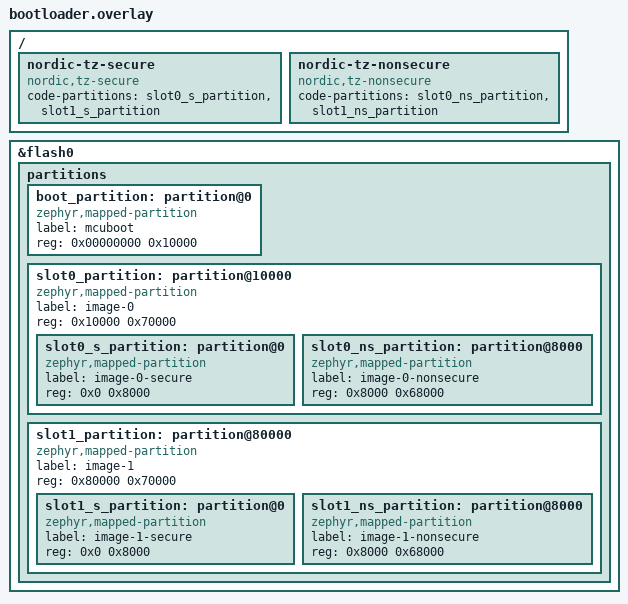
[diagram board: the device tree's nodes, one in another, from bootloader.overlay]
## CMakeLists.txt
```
#
# Copyright (c) 2019 Nordic Semiconductor
#
# SPDX-License-Identifier: LicenseRef-Nordic-5-Clause
#

cmake_minimum_required(VERSION 3.20.0)

find_package(Zephyr REQUIRED HINTS $ENV{ZEPHYR_BASE})
project(lwm2m-carrier)

# Generate hex files from pem files
set(gen_dir ${CMAKE_CURRENT_BINARY_DIR}/certs)
zephyr_include_directories(${gen_dir})
generate_inc_file_for_target(
    app
    certs/DigiCertGlobalRootCA.pem
    ${gen_dir}/DigiCertGlobalRootCA.pem.inc
    )
generate_inc_file_for_target(
    app
    certs/DigiCertGlobalRootG2.pem
    ${gen_dir}/DigiCertGlobalRootG2.pem.inc
    )
generate_inc_file_for_target(
    app
    certs/DSTRootCA-X3.pem
    ${gen_dir}/DSTRootCA-X3.pem.inc
    )

# NORDIC SDK APP START
target_sources(app PRIVATE src/main.c)
target_sources(app PRIVATE src/carrier_certs.c)
# NORDIC SDK APP END
```

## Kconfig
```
#
# Copyright (c) 2022 Nordic Semiconductor ASA
#
# SPDX-License-Identifier: LicenseRef-Nordic-5-Clause
#

menu "Custom PSK"
config CARRIER_APP_PSK
	string "LwM2M Pre-Shared Key (PSK)"
	default ""
	help
	  Hexadecimal PSK used to connect to the LwM2M server.

endmenu

menu "Zephyr Kernel"
source "Kconfig.zephyr"
endmenu
```

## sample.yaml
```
sample:
  name: LwM2M carrier sample
tests:
  sample.cellular.lwm2m_carrier:
    sysbuild: true
    build_only: true
    integration_platforms:
      - nrf9151dk/nrf9151/ns
    platform_allow:
      - nrf9151dk/nrf9151/ns
    tags:
      - ci_build
      - sysbuild
      - ci_samples_cellular
  sample.cellular.lwm2m_carrier.shell:
    sysbuild: true
    build_only: true
    integration_platforms:
      - nrf9151dk/nrf9151/ns
    platform_allow:
      - nrf9151dk/nrf9151/ns
    extra_args: EXTRA_CONF_FILE="overlay-shell.conf"
    tags:
      - ci_build
      - sysbuild
      - ci_samples_cellular
  sample.cellular.lwm2m_carrier.softbank:
    sysbuild: true
    build_only: true
    integration_platforms:
      - nrf9151dk/nrf9151/ns
    platform_allow:
      - nrf9151dk/nrf9151/ns
    extra_args:
      - EXTRA_CONF_FILE="overlay-softbank.conf"
      - SB_EXTRA_CONF_FILE="sysbuild-softbank.conf"
      - EXTRA_DTC_OVERLAY_FILE="bootloader.overlay"
    tags:
      - ci_build
      - sysbuild
      - ci_samples_cellular
  sample.cellular.lwm2m_carrier.lgu:
    sysbuild: true
    build_only: true
    integration_platforms:
      - nrf9151dk/nrf9151/ns
    platform_allow:
      - nrf9151dk/nrf9151/ns
    extra_args:
      - EXTRA_CONF_FILE="overlay-lgu.conf"
      - SB_EXTRA_CONF_FILE="sysbuild-lgu.conf"
      - EXTRA_DTC_OVERLAY_FILE="bootloader.overlay"
    tags:
      - ci_build
      - sysbuild
      - ci_samples_cellular
```

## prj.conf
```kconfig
#
# Copyright (c) 2019 Nordic Semiconductor ASA
#
# SPDX-License-Identifier: LicenseRef-Nordic-5-Clause
#

# TF-M config
CONFIG_TFM_PROFILE_TYPE_MINIMAL=y

CONFIG_LWM2M_CARRIER=y

# LwM2M carrier is only compiled for hard-float
CONFIG_FPU=y
CONFIG_FP_HARDABI=y

# Modem library
CONFIG_NRF_MODEM_LIB=y

# LTE link control
CONFIG_LTE_LINK_CONTROL=y
CONFIG_LTE_LC_PDN_MODULE=y

# SMS library
CONFIG_SMS=y

# Download client for DFU
CONFIG_DOWNLOADER=y
CONFIG_DOWNLOADER_MAX_FILENAME_SIZE=230

# AT Monitor
CONFIG_AT_MONITOR=y
CONFIG_AT_MONITOR_HEAP_SIZE=320

# Credential management
CONFIG_MODEM_KEY_MGMT=y

# Non-volatile Storage
CONFIG_FLASH=y
CONFIG_FLASH_PAGE_LAYOUT=y
CONFIG_NVS=y
CONFIG_MPU_ALLOW_FLASH_WRITE=y

# Heap and stacks
CONFIG_HEAP_MEM_POOL_SIZE=4096
CONFIG_SYSTEM_WORKQUEUE_STACK_SIZE= 1536
CONFIG_MAIN_STACK_SIZE=1536

# General config
CONFIG_NETWORKING=y
CONFIG_NET_NATIVE=n
CONFIG_NET_SOCKETS=y
CONFIG_POSIX_API=y
CONFIG_NET_SOCKETS_OFFLOAD=y

# Allow the non-secure application to request reboot
CONFIG_REBOOT=y

# DFU target library
CONFIG_DFU_TARGET=y

# IPv4 (IPv6 is enabled by default)
CONFIG_NET_IPV4=y
```

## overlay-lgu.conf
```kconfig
#
# Copyright (c) 2024 Nordic Semiconductor
#
# SPDX-License-Identifier: LicenseRef-Nordic-5-Clause
#

# LG U+
CONFIG_LWM2M_CARRIER_LG_UPLUS=y

# Application FOTA
CONFIG_DFU_TARGET_MCUBOOT=y
CONFIG_IMG_MANAGER=y
CONFIG_STREAM_FLASH=y
CONFIG_STREAM_FLASH_ERASE=y
CONFIG_FLASH_MAP=y
```

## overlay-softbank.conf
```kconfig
#
# Copyright (c) 2024 Nordic Semiconductor
#
# SPDX-License-Identifier: LicenseRef-Nordic-5-Clause
#

# SoftBank
CONFIG_LWM2M_CARRIER_SOFTBANK=y
CONFIG_LWM2M_CARRIER_SOFTBANK_DIVIDED_FOTA=y

# Override default PDP context
CONFIG_LTE_LC_PDN_DEFAULTS_OVERRIDE=y
CONFIG_LTE_LC_PDN_DEFAULT_FAM_NONIP=y

# Set NB-IoT system mode
CONFIG_LTE_NETWORK_MODE_NBIOT=y

# Application FOTA
CONFIG_DFU_TARGET_MCUBOOT=y
CONFIG_BOOTLOADER_MCUBOOT=y
CONFIG_IMG_MANAGER=y
CONFIG_STREAM_FLASH=y
CONFIG_STREAM_FLASH_ERASE=y
CONFIG_FLASH_MAP=y
```

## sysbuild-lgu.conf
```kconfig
#
# Copyright (c) 2019 Nordic Semiconductor ASA
#
# SPDX-License-Identifier: LicenseRef-Nordic-5-Clause
#

SB_CONFIG_BOOTLOADER_MCUBOOT=y
```

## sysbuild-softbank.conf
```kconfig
#
# Copyright (c) 2019 Nordic Semiconductor ASA
#
# SPDX-License-Identifier: LicenseRef-Nordic-5-Clause
#

SB_CONFIG_LWM2M_CARRIER_DIVIDED_DFU=y
SB_CONFIG_BOOTLOADER_MCUBOOT=y
```

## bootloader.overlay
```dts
/*
 * Copyright (c) 2026 Nordic Semiconductor ASA
 *
 * SPDX-License-Identifier: LicenseRef-Nordic-5-Clause
 */

/delete-node/ &slot0_partition;

&flash0 {
	/*
	 * Replace single slot0 with boot, slot0 and slot1. (Keep storage_partition the same).
	 *
	 * 0x0000_0000  MCUboot                        ( 65 kB)
	 * 0x0000_c000  Primary area                   (448 kB)
	 *   0x0000_c000  Primary secure image         ( 32 kB)
	 *   0x0001_8000  Primary non-secure image     (416 kB)
	 * 0x0007_5000  Secondary area                 (448 kB)
	 *    0x0007_5000  Secondary secure image      ( 32 kB)
	 *    0x0008_1000  Secondary non-secure image  (416 kB)
	 */
	partitions {
		ranges;
		#address-cells = <1>;
		#size-cells = <1>;

		boot_partition: partition@0 {
			compatible = "zephyr,mapped-partition";
			label = "mcuboot";
			reg = <0x00000000 0x10000>;
		};

		slot0_partition: partition@10000 {
			compatible = "zephyr,mapped-partition";
			label = "image-0";
			reg = <0x10000 0x70000>;
			ranges = <0x0 0x10000 0x70000>;
			#address-cells = <1>;
			#size-cells = <1>;

			slot0_s_partition: partition@0 {
				compatible = "zephyr,mapped-partition";
				label = "image-0-secure";
				reg = <0x0 0x8000>;
			};

			slot0_ns_partition: partition@8000 {
				compatible = "zephyr,mapped-partition";
				label = "image-0-nonsecure";
				reg = <0x8000 0x68000>;
			};
		};

		slot1_partition: partition@80000 {
			compatible = "zephyr,mapped-partition";
			label = "image-1";
			reg = <0x80000 0x70000>;
			ranges = <0x0 0x80000 0x70000>;
			#address-cells = <1>;
			#size-cells = <1>;

			slot1_s_partition: partition@0 {
				compatible = "zephyr,mapped-partition";
				label = "image-1-secure";
				reg = <0x0 0x8000>;
			};

			slot1_ns_partition: partition@8000 {
				compatible = "zephyr,mapped-partition";
				label = "image-1-nonsecure";
				reg = <0x8000 0x68000>;
			};
		};
	};
};

/ {
	/delete-node/ nordic-tz-secure;
	/delete-node/ nordic-tz-nonsecure;

	nordic-tz-secure {
		compatible = "nordic,tz-secure";
		code-partitions = <&slot0_s_partition>,
				  <&slot1_s_partition>;
	};

	nordic-tz-nonsecure {
		compatible = "nordic,tz-nonsecure";
		code-partitions = <&slot0_ns_partition>,
				  <&slot1_ns_partition>;
	};
};
```

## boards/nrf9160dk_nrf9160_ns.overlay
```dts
/*
 * Copyright (c) 2026 Nordic Semiconductor ASA
 *
 * SPDX-License-Identifier: LicenseRef-Nordic-5-Clause
 */

#include <samples/cellular/nrf91_no_bootloader_partitions.dtsi>

/ {
	chosen {
		nordic,lwm2m-carrier-partition = &lwm2m_carrier_partition;
		zephyr,settings-partition = &settings_storage_partition;
	};
};

&storage_partition {
	compatible = "zephyr,mapped-partition";
	label = "storage";
	reg = <0x000f8000 0x8000>;
	ranges = <0x0 0x000f8000 0x8000>;
	#address-cells = <1>;
	#size-cells = <1>;

	lwm2m_carrier_partition: partition@0 {
		compatible = "zephyr,mapped-partition";
		label = "lwm2m-carrier";
		reg = <0x00000000 0x3000>;
	};

	settings_storage_partition: partition@3000 {
		compatible = "zephyr,mapped-partition";
		label = "settings-storage";
		reg = <0x00003000 0x5000>;
	};
};

#include <samples/cellular/nrf91_sram_partitions.dtsi>
```

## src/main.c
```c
/*
 * Copyright (c) 2019 Nordic Semiconductor ASA
 *
 * SPDX-License-Identifier: LicenseRef-Nordic-5-Clause
 */

#include <zephyr/kernel.h>
#include <modem/nrf_modem_lib.h>
#include <modem/lte_lc.h>

#ifdef CONFIG_LWM2M_CARRIER
#include <lwm2m_carrier.h>
#include "carrier_certs.h"

NRF_MODEM_LIB_ON_INIT(main_init_hook, on_modem_lib_init, NULL);

static void lte_event_handler(const struct lte_lc_evt *const evt)
{
	/* This event handler is not in use here. */
	ARG_UNUSED(evt);
}

static void on_modem_lib_init(int ret, void *ctx)
{
	int err;
	static bool m_first_init = true;

	ARG_UNUSED(ctx);

	if (ret != 0) {
		printk("Modem library did not initialize: %d\n", ret);
		return;
	}

	/* Let the application write the credentials first and then bring the link up! */
	if (m_first_init) {
		err = carrier_cert_provision();
		if (err) {
			printk("failed to provision CA certificates\n");
		}

#ifdef LWM2M_CARRIER_SETTINGS
		if (!lwm2m_settings_enable_custom_server_config_get()) {
			err = carrier_psk_provision();
			if (err) {
				printk("failed to provision PSK\n");
			}
		}
#else
		err = carrier_psk_provision();
		if (err) {
			printk("failed to provision PSK\n");
		}
#endif /* LWM2M_CARRIER_SETTINGS */

		lte_lc_register_handler(lte_event_handler);

		m_first_init = false;
	}
}

void print_err(const lwm2m_carrier_event_t *evt)
{
	const lwm2m_carrier_event_error_t *err = evt->data.error;

	static const char *strerr[] = {
		[LWM2M_CARRIER_ERROR_NO_ERROR] =
			"No error",
		[LWM2M_CARRIER_ERROR_BOOTSTRAP] =
			"Bootstrap error",
		[LWM2M_CARRIER_ERROR_LTE_LINK_UP_FAIL] =
			"Failed to connect to the LTE network",
		[LWM2M_CARRIER_ERROR_LTE_LINK_DOWN_FAIL] =
			"Failed to disconnect from the LTE network",
		[LWM2M_CARRIER_ERROR_FOTA_FAIL] =
			"Modem firmware update failed",
		[LWM2M_CARRIER_ERROR_CONFIGURATION] =
			"Configuration failure",
		[LWM2M_CARRIER_ERROR_INIT] =
			"Initialization failure",
		[LWM2M_CARRIER_ERROR_CONNECT] =
			"Connection failure",
	};

	__ASSERT(PART_OF_ARRAY(strerr[err->type]),
		 "Unhandled liblwm2m_carrier error");

	printk("%s, reason %d\n", strerr[err->type], err->value);
}

void print_deferred(const lwm2m_carrier_event_t *evt)
{
	const lwm2m_carrier_event_deferred_t *def = evt->data.deferred;

	static const char *strdef[] = {
		[LWM2M_CARRIER_DEFERRED_NO_REASON] =
			"No reason given",
		[LWM2M_CARRIER_DEFERRED_PDN_ACTIVATE] =
			"Failed to activate PDN",
		[LWM2M_CARRIER_DEFERRED_BOOTSTRAP_NO_ROUTE] =
			"No route to bootstrap server",
		[LWM2M_CARRIER_DEFERRED_BOOTSTRAP_CONNECT] =
			"Failed to connect to bootstrap server",
		[LWM2M_CARRIER_DEFERRED_BOOTSTRAP_SEQUENCE] =
			"Bootstrap sequence not completed",
		[LWM2M_CARRIER_DEFERRED_SERVER_NO_ROUTE] =
			"No route to server",
		[LWM2M_CARRIER_DEFERRED_SERVER_CONNECT] =
			"Failed to connect to server",
		[LWM2M_CARRIER_DEFERRED_SERVER_REGISTRATION] =
			"Server registration sequence not completed",
		[LWM2M_CARRIER_DEFERRED_SERVICE_UNAVAILABLE] =
			"Server in maintenance mode",
		[LWM2M_CARRIER_DEFERRED_SIM_MSISDN] =
			"Waiting for SIM MSISDN",
	};

	__ASSERT(PART_OF_ARRAY(strdef[def->reason]),
		 "Unhandled deferred reason");

	printk("Reason: %s, timeout: %d seconds\n", strdef[def->reason],
		def->timeout);
}

void print_app_data(const lwm2m_carrier_event_t *evt)
{
	const uint16_t *path = evt->data.app_data->path;
	const uint8_t event_type = evt->data.app_data->type;

	static const char *const app_data_event_types[] = {
		[LWM2M_CARRIER_APP_DATA_EVENT_DATA_WRITE] = "DATA_WRITE",
		[LWM2M_CARRIER_APP_DATA_EVENT_OBSERVE_START] = "OBSERVE_START",
		[LWM2M_CARRIER_APP_DATA_EVENT_OBSERVE_STOP] = "OBSERVE_STOP",
	};

	char path_string[sizeof("/65535/65535/65535/65535")];
	uint32_t offset = 0;

	for (int i = 0; i < evt->data.app_data->path_len; i++) {
		offset += snprintf(&path_string[offset], sizeof(path_string) - offset,
				   "/%hu", path[i]);
		if (offset >= sizeof(path_string)) {
			break;
		}
	}

	printk("App data event type: %s, path: %s\n",
		app_data_event_types[event_type], path_string);
}

int lwm2m_carrier_event_handler(const lwm2m_carrier_event_t *event)
{
	int err = 0;

	switch (event->type) {
	case LWM2M_CARRIER_EVENT_LTE_LINK_UP:
		printk("LWM2M_CARRIER_EVENT_LTE_LINK_UP\n");
		err = lte_lc_connect_async(NULL);
		break;
	case LWM2M_CARRIER_EVENT_LTE_LINK_DOWN:
		printk("LWM2M_CARRIER_EVENT_LTE_LINK_DOWN\n");
		err = lte_lc_offline();
		break;
	case LWM2M_CARRIER_EVENT_LTE_POWER_OFF:
		printk("LWM2M_CARRIER_EVENT_LTE_POWER_OFF\n");
		err = lte_lc_power_off();
		break;
	case LWM2M_CARRIER_EVENT_BOOTSTRAPPED:
		printk("LWM2M_CARRIER_EVENT_BOOTSTRAPPED\n");
		break;
	case LWM2M_CARRIER_EVENT_REGISTERED:
		printk("LWM2M_CARRIER_EVENT_REGISTERED\n");
		break;
	case LWM2M_CARRIER_EVENT_DEREGISTERED:
		printk("LWM2M_CARRIER_EVENT_DEREGISTERED\n");
		break;
	case LWM2M_CARRIER_EVENT_DEFERRED:
		printk("LWM2M_CARRIER_EVENT_DEFERRED\n");
		print_deferred(event);
		break;
	case LWM2M_CARRIER_EVENT_FOTA_START:
		printk("LWM2M_CARRIER_EVENT_FOTA_START\n");
		break;
	case LWM2M_CARRIER_EVENT_FOTA_SUCCESS:
		printk("LWM2M_CARRIER_EVENT_FOTA_SUCCESS\n");
		break;
	case LWM2M_CARRIER_EVENT_REBOOT:
		printk("LWM2M_CARRIER_EVENT_REBOOT\n");
		break;
	case LWM2M_CARRIER_EVENT_MODEM_DOMAIN:
		printk("LWM2M_CARRIER_EVENT_MODEM_DOMAIN\n");
		break;
	case LWM2M_CARRIER_EVENT_APP_DATA:
		printk("LWM2M_CARRIER_EVENT_APP_DATA\n");
		print_app_data(event);
		break;
	case LWM2M_CARRIER_EVENT_MODEM_INIT:
		printk("LWM2M_CARRIER_EVENT_MODEM_INIT\n");
		err = nrf_modem_lib_init();
		break;
	case LWM2M_CARRIER_EVENT_MODEM_SHUTDOWN:
		printk("LWM2M_CARRIER_EVENT_MODEM_SHUTDOWN\n");
		err = nrf_modem_lib_shutdown();
		break;
	case LWM2M_CARRIER_EVENT_ERROR_CODE_RESET:
		printk("LWM2M_CARRIER_EVENT_ERROR_CODE_RESET\n");
		break;
	case LWM2M_CARRIER_EVENT_ERROR:
		printk("LWM2M_CARRIER_EVENT_ERROR\n");
		print_err(event);
		break;
	}

	return err;
}
#endif /* CONFIG_LWM2M_CARRIER */

int main(void)
{
	printk("LWM2M Carrier library sample.\n");

	int err = nrf_modem_lib_init();

	if (err < 0) {
		printk("Failed to initialize modem library\n");
	}

	/* Connect to the LTE network. */
	lte_lc_connect_async(NULL);

	return 0;
}
```

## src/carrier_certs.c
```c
/*
 * Copyright (c) 2021 Nordic Semiconductor ASA
 *
 * SPDX-License-Identifier: LicenseRef-Nordic-5-Clause
 */

#include <stdint.h>
#include <string.h>
#include <zephyr/toolchain.h>
#include <zephyr/sys/util.h>
#include <zephyr/sys/printk.h>
#include <modem/modem_key_mgmt.h>
#include "carrier_certs.h"

#ifdef CONFIG_LWM2M_CARRIER

#define ORANGE "\e[0;33m"
#define GREEN "\e[0;32m"
#define NORMAL "\e[0m"

static const char ca411[] = {
	/* VzW and Motive */
	#include "DigiCertGlobalRootG2.pem.inc"
};
static const char ca412[] = {
	/* VzW and Motive */
	#include "DigiCertGlobalRootCA.pem.inc"
};
static const char ca413[] = {
	/* Coiote */
	#include "DSTRootCA-X3.pem.inc"
};

BUILD_ASSERT(sizeof(ca411) < KB(4), "Cert is too large");
BUILD_ASSERT(sizeof(ca412) < KB(4), "Cert is too large");
BUILD_ASSERT(sizeof(ca413) < KB(4), "Cert is too large");

static const struct {
	uint16_t tag;
	const char *data;
	size_t len;
} certs[] = {
	{
		.tag = 411,
		.data = ca411,
		.len = sizeof(ca411),
	},
	{
		.tag = 412,
		.data = ca412,
		.len = sizeof(ca412),
	},
	{
		.tag = 413,
		.data = ca413,
		.len = sizeof(ca413),
	}
};

int carrier_cert_provision(void)
{
	int err;
	bool mismatch = 0;
	bool provisioned;

	for (int i = 0; i < ARRAY_SIZE(certs); i++) {
		err = modem_key_mgmt_exists(
			certs[i].tag, MODEM_KEY_MGMT_CRED_TYPE_CA_CHAIN, &provisioned);

		if (err) {
			return -1;
		}

		if (provisioned) {
			err = modem_key_mgmt_cmp(
				certs[i].tag, MODEM_KEY_MGMT_CRED_TYPE_CA_CHAIN,
				certs[i].data, certs[i].len);

			/* 0 on match, 1 otherwise; like memcmp() */
			mismatch = err;

			printk("Certificate found, tag %d: %s\n" NORMAL, certs[i].tag,
				mismatch ? ORANGE "mismatch" : GREEN "match");
		} else {
			printk("Certificate tag %d " ORANGE "not found\n" NORMAL,
				  certs[i].tag);
		}

		if (mismatch || !provisioned) {
			/* overwrite the certificate */
			err = modem_key_mgmt_write(
				certs[i].tag, MODEM_KEY_MGMT_CRED_TYPE_CA_CHAIN,
				certs[i].data, certs[i].len);
			if (err) {
				printk(ORANGE "ERROR: " NORMAL
				  "Unable to provision certificate, err: %d\n", err);
				return -1;
			}
			printk("Certificate provisioned, tag %d\n", certs[i].tag);
		}
	}
	return 0;
}

int carrier_psk_provision(void)
{
	if (CONFIG_LWM2M_CARRIER_SERVER_SEC_TAG) {
		char *p_psk = CONFIG_CARRIER_APP_PSK;

		if (strlen(p_psk) <= 0) {
			return 0;
		}

		uint8_t psk_len = strlen(p_psk);
		int err = 0;

		if (psk_len > 0) {
			err = modem_key_mgmt_write(CONFIG_LWM2M_CARRIER_SERVER_SEC_TAG,
			MODEM_KEY_MGMT_CRED_TYPE_PSK, p_psk, psk_len);
			printk("PSK provisioned, tag %d\n", CONFIG_LWM2M_CARRIER_SERVER_SEC_TAG);
		}
		if (err) {
			printk("Unable to provision PSK, tag %d\n",
				CONFIG_LWM2M_CARRIER_SERVER_SEC_TAG);
			return -1;
		}
	}

	return 0;
}

#endif /* CONFIG_LWM2M_CARRIER */
```
